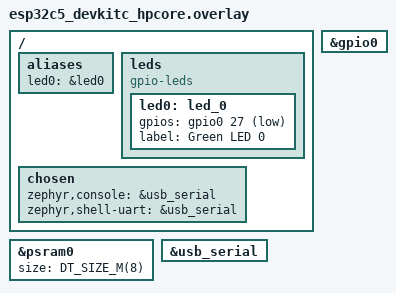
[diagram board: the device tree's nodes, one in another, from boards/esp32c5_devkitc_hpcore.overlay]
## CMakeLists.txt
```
# SPDX-License-Identifier: Apache-2.0

cmake_minimum_required(VERSION 3.20.0)

# Add wifi-credentials snippet
if(NOT wifi-credentials IN_LIST SNIPPET)
  set(SNIPPET wifi-credentials ${SNIPPET} CACHE STRING "wifi-credentials snippet" FORCE)
endif()

if(NOT espressif-psram-8M IN_LIST SNIPPET)
  set(SNIPPET espressif-psram-8M ${SNIPPET} CACHE STRING "espressif-psram-8M snippet" FORCE)
endif()

if(NOT espressif-psram-wifi IN_LIST SNIPPET)
  set(SNIPPET espressif-psram-wifi ${SNIPPET} CACHE STRING "espressif-psram-wifi snippet" FORCE)
endif()

set(mcuboot_key_file ${CMAKE_CURRENT_SOURCE_DIR}/key.pem)
set(mcuboot_CONFIG_BOOT_SIGNATURE_KEY_FILE "\"${mcuboot_key_file}\"")

# Load .env file into environment variables if it exists
if(EXISTS "${CMAKE_CURRENT_SOURCE_DIR}/.env")
  file(STRINGS "${CMAKE_CURRENT_SOURCE_DIR}/.env" ENV_VARS ENCODING UTF-8)
  foreach(line ${ENV_VARS})
    # Ignore empty lines and lines starting with '#'
    if(NOT line MATCHES "^[ \t]*#" AND line MATCHES "^([^=]+)=(.*)$")
      string(STRIP "${CMAKE_MATCH_1}" key)
      string(STRIP "${CMAKE_MATCH_2}" value)
      # Strip surrounding quotes if present
      string(REGEX REPLACE "^[\"\'](.*)[\"\']$" "\\1" value "${value}")
      set(ENV{${key}} "${value}")
    endif()
  endforeach()
endif()

find_package(Zephyr REQUIRED HINTS $ENV{ZEPHYR_BASE})
project(wifi)


# Verify that this sample is built through sysbuild to ensure MCUboot is
# automatically included and that sample specific MCUboot configurations are
# used when building MCUboot.
test_sysbuild()

FILE(GLOB app_sources src/*.c)
target_sources(app PRIVATE ${app_sources})

# From MQTT publisher sample
include(${ZEPHYR_BASE}/samples/net/common/common.cmake)
```

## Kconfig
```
# Config options for mqtt_publisher sample application

# Copyright (c) 2020 Intel Corporation
# SPDX-License-Identifier: Apache-2.0

mainmenu "Networking mqtt_publisher sample application"

config WIFI_SSID
	string "Wi-Fi SSID"
	default "$(WIFI_SSID)" if "$(WIFI_SSID)" != ""
	default "zephyr"

config WIFI_PASSWORD
	string "Wi-Fi Password"
	default "$(WIFI_PASSWORD)" if "$(WIFI_PASSWORD)" != ""
	default "19234567"

config WIFI_SECURITY_TYPE
	string "Wi-Fi Security Type"
	default "WIFI_SECURITY_TYPE_PSK"

config NET_SAMPLE_APP_MAX_ITERATIONS
	int "Number of times to Publish sample MQTT messages"
	default 500
	help
	  Send sample MQTT messages this many times in a MQTT connection
	  before exiting. A value of zero means that the messages are sent
	  forever.

config NET_SAMPLE_APP_MAX_CONNECTIONS
	int "Number of times to connect to the MQTT server"
	default 0
	help
	  Number of times to connect to the MQTT server. With each connection
	  send NET_SAMPLE_APP_MAX_ITERATIONS amount of MQTT sample messages.
	  A value of zero means to continue forever.

# From secure MQTT sample application
config NET_SAMPLE_MQTT_BROKER_HOSTNAME
	string "Hostname of MQTT broker"
	default "$(MQTT_BROKER)" if "$(MQTT_BROKER)" != ""
	default "test.mosquitto.org"
	help
	  MQTT broker's hostname or IP address.

config NET_SAMPLE_MQTT_BROKER_PORT
	string "MQTT Broker Connection Port"
	default "1883"
	help
	  Port through which the application should connect to the MQTT broker.
	  Secure MQTT uses port 8883.

config NET_SAMPLE_MQTT_PUB_TOPIC
	string "The MQTT topic the application should publish data to"
	default "technaid_sl/techstim"

config NET_SAMPLE_MQTT_SUB_TOPIC_CMD
	string "The MQTT topic the application will receive commands on"
	default "technaid_sl/techstim"

config NET_SAMPLE_MQTT_PUBLISH_INTERVAL
	int "Interval between MQTT publishes (in seconds)"
	default 10
	help
	  This config determines the frequency at which MQTT publishes occur.

choice NET_SAMPLE_MQTT_QOS
	prompt "Quality of Service level used for MQTT publish and subscribe"
	default NET_SAMPLE_MQTT_QOS_1_AT_LEAST_ONCE

config NET_SAMPLE_MQTT_QOS_0_AT_MOST_ONCE
	bool "QoS 0 / At most once delivery"
	help
	  No acknowledgment needed for published message.

config NET_SAMPLE_MQTT_QOS_1_AT_LEAST_ONCE
	bool "QoS 1 / At least once delivery"
	help
	  If acknowledgment expected for published message, duplicate messages permitted.

config NET_SAMPLE_MQTT_QOS_2_EXACTLY_ONCE
	bool "QoS 2 / Exactly once delivery"
	help
	   Acknowledgment expected and message shall be published only once.

endchoice

config NET_SAMPLE_MQTT_PAYLOAD_SIZE
	int "Size of MQTT payload in bytes"
	default 128

config TECHSTIM_DEV_DESC_PAYLOAD_SIZE
	int "Size of MQTT payload in bytes"
	default 512


source "Kconfig.zephyr"
```

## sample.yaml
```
common:
  harness: net
  tags:
    - net
    - wifi
sample:
  description: Test wifi driver and APIs functionality
  name: WiFi sample app
tests:
  sample.net.wifi:
    platform_allow:
      - cc3220sf_launchxl
      - disco_l475_iot1
      - reel_board
      - siwx917_rb4338a
    integration_platforms:
      - cc3220sf_launchxl
  sample.net.wifi.mikroe_wifi_bt_click:
    extra_args: SHIELD=mikroe_wifi_bt_click_mikrobus
    platform_allow: lpcxpresso55s69/lpc55s69/cpu0
  sample.net.wifi.esp_8266:
    extra_args: SHIELD=esp_8266
    platform_allow: sam4e_xpro
  sample.net.wifi.esp_8266_arduino:
    extra_args: SHIELD=esp_8266_arduino
    platform_allow:
      - frdm_k64f
      - disco_l475_iot1
    integration_platforms:
      - frdm_k64f
  sample.net.wifi.inventek_eswifi_arduino_uart:
    extra_args: SHIELD=inventek_eswifi_arduino_uart
    platform_allow:
      - frdm_k64f
      - nucleo_f767zi
    integration_platforms:
      - frdm_k64f
  sample.net.wifi.inventek_eswifi_arduino_spi:
    extra_args: SHIELD=inventek_eswifi_arduino_spi
    platform_allow:
      - frdm_k64f
      - nucleo_f767zi
    integration_platforms:
      - frdm_k64f
  sample.net.wifi.nrf70dk:
    extra_args:
      - CONFIG_BUILD_ONLY_NO_BLOBS=y
      - CONFIG_WIFI_CREDENTIALS=y
      - CONFIG_FLASH=y
      - CONFIG_FLASH_MAP=y
      - CONFIG_NVS=y
      - CONFIG_SETTINGS=y
    platform_allow:
      - nrf7002dk/nrf5340/cpuapp
      - nrf7002dk/nrf5340/cpuapp/nrf7001
    integration_platforms:
      - nrf7002dk/nrf5340/cpuapp
      - nrf7002dk/nrf5340/cpuapp/nrf7001
  sample.net.wifi.nrf7002ek:
    extra_args:
      - CONFIG_BUILD_ONLY_NO_BLOBS=y
      - SHIELD=nrf7002ek
    platform_allow:
      - nrf5340dk/nrf5340/cpuapp
      - nucleo_h723zg
    integration_platforms:
      - nrf5340dk/nrf5340/cpuapp
      - nucleo_h723zg
  sample.net.wifi.nrf7002eb:
    extra_args:
      - CONFIG_NRF70_UTIL=y
      - CONFIG_BUILD_ONLY_NO_BLOBS=y
      - SHIELD=nrf7002eb
    platform_allow:
      - thingy53/nrf5340/cpuapp
    integration_platforms:
      - thingy53/nrf5340/cpuapp
  sample.net.wifi.nrf7002eb2:
    extra_args:
      - CONFIG_BUILD_ONLY_NO_BLOBS=y
      - SHIELD=nrf7002eb2
    platform_allow:
      - nrf54lm20dk/nrf54lm20b/cpuapp
      - nrf54lm20dk/nrf54lm20b/cpuapp/ns
    integration_platforms:
      - nrf54lm20dk/nrf54lm20b/cpuapp
  sample.net.wifi.nxp_wifi:
    extra_args:
      - CONFIG_BUILD_ONLY_NO_BLOBS=y
    platform_allow:
      - frdm_rw612
      - rd_rw612_bga
  sample.net.wifi.esp32:
    extra_args:
      - CONFIG_BUILD_ONLY_NO_BLOBS=y
    platform_allow:
      - esp32_devkitc/esp32/procpu
      - esp32s2_devkitc
      - esp32c3_devkitc
      - esp32s3_devkitc/esp32s3/procpu
      - esp8684_devkitm
      - esp32c6_devkitc/esp32c6/hpcore
  sample.net.wifi.siwx91x_offloaded:
    extra_args:
      - CONFIG_WIFI_SILABS_SIWX91X_NET_STACK_OFFLOAD=y
    platform_allow:
      - siwx917_rb4338a
```

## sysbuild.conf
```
# Sysbuild configuration file.

# Enable MCUboot using overwrite only mode for this sample.
SB_CONFIG_BOOTLOADER_MCUBOOT=y
SB_CONFIG_MCUBOOT_MODE_OVERWRITE_ONLY=y
```

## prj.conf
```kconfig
CONFIG_EARLY_CONSOLE=y

CONFIG_NETWORKING=y
CONFIG_TEST_RANDOM_GENERATOR=y

CONFIG_MAIN_STACK_SIZE=5200
CONFIG_SHELL_STACK_SIZE=5200
CONFIG_NET_TX_STACK_SIZE=2048
CONFIG_NET_RX_STACK_SIZE=2048

CONFIG_NET_PKT_RX_COUNT=10
CONFIG_NET_PKT_TX_COUNT=10
CONFIG_NET_BUF_RX_COUNT=16
CONFIG_NET_BUF_TX_COUNT=16
CONFIG_NET_MAX_CONTEXTS=10
CONFIG_NET_DHCPV4=y

CONFIG_NET_IPV4=y
CONFIG_NET_IPV6=n

CONFIG_NET_TCP=y

CONFIG_NET_LOG=y
CONFIG_INIT_STACKS=y

CONFIG_NET_SHELL=y

CONFIG_NET_STATISTICS=y
CONFIG_NET_STATISTICS_PERIODIC_OUTPUT=n

CONFIG_WIFI=y
CONFIG_WIFI_LOG_LEVEL_ERR=y
CONFIG_NET_L2_WIFI_SHELL=y
# printing of scan results puts pressure on queues in new locking
# design in net_mgmt. So, use a higher timeout for a crowded
# environment.
CONFIG_NET_MGMT_EVENT_QUEUE_TIMEOUT=5000
CONFIG_NET_MGMT_EVENT_QUEUE_SIZE=16

# Implementing I2C shell
CONFIG_GPIO=y

CONFIG_I2C=y
CONFIG_I2C_SHELL=y

CONFIG_NET_BUF_POOL_USAGE=y
# CONFIG_ESP32_WIFI_STATIC_RX_MGMT_BUFFER=y
CONFIG_ESP32_WIFI_DYNAMIC_RX_MGMT_BUFFER=y

# From MQTT publisher sample
# Enable the MQTT Lib
CONFIG_MQTT_LIB=y
CONFIG_NET_LOG=y
CONFIG_NET_CONNECTION_MANAGER=y

CONFIG_POSIX_API=y

# CONFIG_NET_CONFIG_SETTINGS=y
# # CONFIG_NET_CONFIG_MY_IPV6_ADDR="2001:db8::1"
# # CONFIG_NET_CONFIG_PEER_IPV6_ADDR="2001:db8::2"

# # CONFIG_NET_CONFIG_MY_IPV4_ADDR="192.168.1.153"
# CONFIG_NET_CONFIG_PEER_IPV4_ADDR="192.168.1.146"

# Enable JSON
CONFIG_JSON_LIBRARY=y

# Change Serial prompt
CONFIG_SHELL_PROMPT_UART="techstim-uart:~$ "

CONFIG_REBOOT=y

# DFU config
CONFIG_IMG_MANAGER=y
CONFIG_MCUBOOT_IMG_MANAGER=y
CONFIG_MCUBOOT_SHELL=y
CONFIG_UPDATEABLE_IMAGE_NUMBER=1
CONFIG_MCUBOOT_BOOTUTIL_LIB=y

# # Flash
CONFIG_FLASH=y
CONFIG_STREAM_FLASH=y
CONFIG_FLASH_MAP=y
```

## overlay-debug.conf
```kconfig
# Debugging
CONFIG_STACK_SENTINEL=y
CONFIG_DEBUG_COREDUMP=y
CONFIG_DEBUG_COREDUMP_BACKEND_LOGGING=y
CONFIG_DEBUG_COREDUMP_MEMORY_DUMP_MIN=y
```

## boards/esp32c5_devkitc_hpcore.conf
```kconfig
# To solve issue relate to buffer after a Wi-Fi connection
CONFIG_ESP32_WIFI_DYNAMIC_RX_MGMT_BUFFER=y
```

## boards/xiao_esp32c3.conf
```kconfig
# Maximum power for WEMOS Lolin C3 is between [10, 12]
CONFIG_ESP32_PHY_MAX_TX_POWER=12
```

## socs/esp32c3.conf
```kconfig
CONFIG_ESP32_WIFI_STA_AUTO_DHCPV4=y
```

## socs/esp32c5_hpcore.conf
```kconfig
# CONFIG_ESP32_WIFI_STA_AUTO_DHCPV4=y
```

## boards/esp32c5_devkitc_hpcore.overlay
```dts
/ {
  aliases {
		led0 = &led0;
	};

	leds {
		compatible = "gpio-leds";

		led0: led_0 {
			gpios = <&gpio0 27 GPIO_ACTIVE_LOW>;
			label = "Green LED 0";
		};
	};

  chosen {
    zephyr,console = &usb_serial;
    zephyr,shell-uart = &usb_serial;
	};
};

&gpio0 {
    status = "okay";
};

&psram0 {
  size = <DT_SIZE_M(8)>;
};

&usb_serial {
  status = "okay";
};
```

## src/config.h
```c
/*
 * Copyright (c) 2017 Intel Corporation
 *
 * SPDX-License-Identifier: Apache-2.0
 */

/**
 * TODO:
 * - [] Update IP when there is a Wi-Fi Connection
 * - [] Add the MAC address
 */

#ifndef __CONFIG_H__
#define __CONFIG_H__

#define NO_SERVER_ADDR "0.0.0.0"
#define DEFAULT_SERVER_ADDR CONFIG_NET_SAMPLE_MQTT_BROKER_HOSTNAME

#ifdef CONFIG_NET_CONFIG_SETTINGS
#ifdef CONFIG_NET_IPV6
#define ZEPHYR_ADDR CONFIG_NET_CONFIG_MY_IPV6_ADDR
#define SERVER_ADDR CONFIG_NET_CONFIG_PEER_IPV6_ADDR
#else
#define ZEPHYR_ADDR CONFIG_NET_CONFIG_MY_IPV4_ADDR
#define SERVER_ADDR CONFIG_NET_CONFIG_PEER_IPV4_ADDR
#endif
#else
#ifdef CONFIG_NET_IPV6
#define ZEPHYR_ADDR "2001:db8::1"
#define SERVER_ADDR "2001:db8::2"
#else
#define ZEPHYR_ADDR "192.168.1.101"
#define SERVER_ADDR "0.0.0.0"
#endif
#endif

#if defined(CONFIG_SOCKS)
#define SOCKS5_PROXY_ADDR SERVER_ADDR
#define SOCKS5_PROXY_PORT 1080
#endif

#ifdef CONFIG_MQTT_LIB_TLS
#ifdef CONFIG_MQTT_LIB_WEBSOCKET
#define SERVER_PORT 9001
#else
#define SERVER_PORT 8883
#endif /* CONFIG_MQTT_LIB_WEBSOCKET */
#else
#ifdef CONFIG_MQTT_LIB_WEBSOCKET
#define SERVER_PORT 9001
#else
#define SERVER_PORT 1883
#endif /* CONFIG_MQTT_LIB_WEBSOCKET */
#endif

#define APP_CONNECT_TIMEOUT_MS 2000
#define APP_SLEEP_MSECS 500

#define APP_CONNECT_TRIES 10

#define APP_MQTT_BUFFER_SIZE 128

#define APP_MQTT_KEEPALIVE 4

// MQTT definitions
#define PRODUCT_ID "S0"     // User defined: Where Sx; x= 1,2,4, etc. is for PU, while Sy; y=A, B, C, etc. for CU
#define SERIAL_NUMBER "pu1" // It will be extracted from EFUSE_BLK3 (USER_DATA)

#define MQTT_COMPANY "technaid_sl"
#define MQTT_PRODUCT "techstim"
#define MQTT_PUBLISH_DEVICE_DESCRIPTOR MQTT_COMPANY "/" MQTT_PRODUCT "/" SERIAL_NUMBER "/device_descriptor"
#define MQTT_PUBLISH_PARAMETERS MQTT_COMPANY "/" MQTT_PRODUCT "/" SERIAL_NUMBER "/parameters"
#define MQTT_PUBLISH_INFO MQTT_COMPANY "/" MQTT_PRODUCT "/" SERIAL_NUMBER "/info"
#define MQTT_SUBSCRIBE_IDS MQTT_COMPANY "/" MQTT_PRODUCT "/" SERIAL_NUMBER "/ids"

// #define TARGETS_ARRAY "[" SERIAL_NUMBER "," SERIAL_NUMBER "]"
#define TARGETS_ARRAY "[" SERIAL_NUMBER "," SERIAL_NUMBER "]"

/* descriptor en un único literal de bytes (Little‑Endian) */
#define DEVICE_DESCRIPTOR_BYTES                               \
    "\x26"                     /* Length = 38 */              \
    "\x00\x04"                 /* DescriptorVersion = 1024 */ \
    "\x00"                     /* DeviceClass */              \
    "\x01"                     /* DeviceSubClass */           \
    "\x01"                     /* DeviceID */                 \
    "\x02"                     /* DeviceProtocol */           \
    "\x0D"                     /* MaxPacketSize */            \
    "\x39\x30"                 /* Vendor = 12345 */           \
    "\x0D"                     /* Product */                  \
    "\x00\x04"                 /* BCDDevice = 1024 */         \
    "\x7B\x00\x00\x00"         /* SerialNumber = 123 */       \
    "\x10"                     /* IDs */                      \
    "\x00\x10"                 /* HardwareVersion = 4096 */   \
    "\x00\x04"                 /* FirmwareVersion = 1024 */   \
    "\x0D"                     /* ProtocolsSupported */       \
    "\x68\x01\xA8\xC0"         /* WIP = 192.168.1.104 */      \
    "\x00\x00\x00\x00"         /* CANID */                    \
    "\xB7\x3A\x11\x44\x1B\x00" /* MAC = 00:1B:44:11:3A:B7 */  \
    "\xB8\x0B"                 /* Port = 3000 */              \
    "\x00\xC2\x01\x00"         /* ByteSpeed = 115200 */

/* longitud en bytes */
#define DEVICE_DESCRIPTOR_LEN sizeof(DEVICE_DESCRIPTOR_BYTES) - 1

#define DEVICE_DESCRIPTOR_MACRO "{\n \
\"Length\": 38,\n \
\"DescriptorVersion\": 1024,\n \
\"DeviceClass\": 0,\n \
\"DeviceSubClass\": 1,\n \
\"DeviceID\": 1,\n \
\"DeviceProtocol\": 2,\n \
\"MaxPacketSize\": 13,\n \
\"Vendor\": 12345,\n \
\"Product\": 13,\n \
\"BCDDevice\": 1024,\n \
\"SerialNumber\": 123,\n \
\"IDs\": 16,\n \
\"HardwareVersion\": 4096,\n \
\"FirmwareVersion\": 1024,\n \
\"ProtocolsSupported\": 13,\n \
\"WIP\": 3232235880,\n \
\"CANID\": 0,\n \
\"MAC\": 117106096823,\n \
\"Port\": 3000,\n \
\"ByteSpeed\": 115200,\n \
}"

/* descriptor genérico de un dispositivo Techstim */
typedef struct
{
    uint8_t Length;             /* 38 bytes totales */
    uint16_t DescriptorVersion; /* 1024  (v0.4.0) */
    uint8_t DeviceClass;        /* 0 → Techstim */
    uint8_t DeviceSubClass;     /* 1 → Techstim v2 */
    uint16_t DeviceID;          /* 1 → SA */
    uint8_t DeviceProtocol;     /* 2 → Wi‑Fi */
    uint8_t MaxPacketSize;      /* 13 */
    uint16_t Vendor;            /* 12345  Technaid SL */
    uint8_t Product;            /* 13  Techstim Wi‑Fi register ID */
    uint16_t BCDDevice;         /* 1024  release */
    uint32_t SerialNumber;      /* 123 */
    uint8_t IDs;                /* 16 */
    uint16_t HardwareVersion;   /* 4096  (v0.4.0) */
    uint16_t FirmwareVersion;   /* 1024  (v1.0.0) */
    uint8_t ProtocolsSupported; /* 13 → USB,BT,Wi‑Fi */
    uint32_t WIP;               /* IP en formato host (0xC0A80168=192.168.1.104) */
    uint32_t CANID;             /* 0 → ninguno */
    uint64_t MAC;               /* 0x001B44113AB7 = 00:1B:44:11:3A:B7 */
    uint16_t Port;              /* 3000 */
    uint32_t ByteSpeed;         /* 115200 */
} device_descriptor_t;


/* Estructuras para parámetros de configuración */
typedef struct
{
    int16_t pos_amp[4];
    size_t pos_amp_len;
} pos_amp_t;

typedef struct
{
    int16_t neg_amp[4];
    size_t neg_amp_len;
} neg_amp_t;

typedef struct
{
    int16_t pos_time[4];
    size_t pos_time_len;
} pos_time_t;

typedef struct
{
    int16_t neg_time[4];
    size_t neg_time_len;
} neg_time_t;

typedef struct
{
    int16_t motor_amp[4];
    size_t motor_amp_len;
} umbral_motor_t;

typedef struct
{
    int16_t comfort_amp[4];
    size_t comfort_amp_len;
} umbral_comfort_t;

typedef struct
{
    int16_t max_amp[4];
    size_t max_amp_len;
} max_current_t;

typedef struct
{
    int16_t min_amp[4];
    size_t min_amp_len;
} min_current_t;

/**
 * Parameter index map for product configuration.
 * These values were previously defined as individual PARAM_* macros.
 */
typedef struct
{
    pos_amp_t pos_amp; // Positive amplitude for channels 1-4 [0-100 mA]
    neg_amp_t neg_amp; // Negative amplitude for channels 1-4 [0-100 mA]
    pos_time_t pos_time; // Positive pulse time for channels 1-4 [0-1000 µs]
    neg_time_t neg_time; // Negative pulse time for channels 1-4 [0-1000 µs]

    uint8_t order_channels; // Order of channels [0-3]
    uint8_t repetitions;    // Number of repetitions [single: 0, double: 1, triple: 2]
    uint8_t inv_pulse;      // Invert pulse [0-1]

    umbral_motor_t umbral_motor;   // Motor threshold for channels 1-4 [0-100 mA]
    umbral_comfort_t umbral_comfort; // Comfort threshold for channels 1-4 [0-100 mA]

    min_current_t min_current; // Minimum current for channels 1-4 [0-100 mA]
    max_current_t max_current; // Maximum current for channels 1-4 [0-100 mA]

    uint16_t intra_freq; // Intra-group frequency [0-200 Hz]
    uint16_t group_freq; // Group frequency [0-200 Hz]

    uint16_t upgrade_ramp;   // Upgrade ramp time [0-1000 ms]
    uint16_t downgrade_ramp; // Downgrade ramp time [0-1000 ms]

    uint16_t stimulation_mode; // Stimulation mode [Symmetric: 0, Asymmetric: 1]
    uint16_t delay;            // Delay between positive and negative pulse [100-1000 ms]

    uint16_t device_id;        // Device ID [PRODUCT_ID]
    uint16_t firmware_version; // Firmware version [4096 for v1.0.0, SOFTWARE_VERSION_SEMVER]
    uint16_t error;            // Error code [0 for no error, otherwise specific error codes]
    uint16_t status;           // Status code bitmask ([0/1]: stimulation inactive/active; bit 0: channel 1, bit 1: channel 2, etc.)
    uint16_t enabled;          // Enabled channels bitmask (bit 0 for channel 1, bit 1 for channel 2, etc.)

    uint16_t log_counter; // Log counter for tracking parameter changes (incremented on each change)
    uint16_t qualifier;   // Qualifier Card ID index for the product (similar to PRODUCT_ID)
} parameters_t;

/*******************************************************************************
 *  FIRMWARE VERSION AND CARD ID                                               *
 ******************************************************************************/
#ifdef APPVERSION
#define SOFTWARE_VERSION APP_VERSION_STRING // String format for SW version
// #define SOFTWARE_VERSION_SEMVER ((APP_VERSION_NUMBER) >> 4U)                                                      /* MAJOR.MINOR.PATCH [0xM.mm.P] */
#define SOFTWARE_VERSION_SEMVER ((APP_VERSION_MAJOR << 12U) + (APP_VERSION_MINOR << 4U) + (APP_PATCHLEVEL << 0U)) /* MAJOR.MINOR.PATCH [0xM.mm.P] */
#else
#define SOFTWARE_VERSION "v1.0.0"      // String format for SW version
#define SOFTWARE_VERSION_SEMVER 0x1000U /* MAJOR.MINOR.PATCH [0xM.mm.P] */
#endif

#define HARDWARE_VERSION_SEMVER 0x1000U   /* MAJOR.MINOR.PATCH [0xM.mm.P] */
#define RELEASE_VERSION_SEMVER 0x1000U    /* MAJOR.MINOR.PATCH [0xM.mm.P] */
#define DESCRIPTOR_VERSION_SEMVER 0x1000U /* MAJOR.MINOR.PATCH [0xM.mm.P] */

#define KIND_ID 83    // 'S' in ASCII DEC (0x53) for Tech'S'tim := Stimulation
#define DEFAULT_ID 48 // '0' in ASCII DEC (0x30) for first device
// #define PRODUCT_ID (((KIND_ID) << 8) | (DEFAULT_ID))

#define MAX_PARAMS 68 // [A-Z][AA-AZ][BA-BP]

// Info status values
#define INFO_STATUS_CONNECTED "connected"
#define INFO_STATUS_DISCONNECTED "disconnected"

// Info mode values
#define INFO_MODE_CONTROLLER "controller"   // Controller for PU units
#define INFO_MODE_PERIPHERAL "peripheral"   // Peripheral for CU units

#define MQTT_CLIENTID PRODUCT_ID

#endif
```

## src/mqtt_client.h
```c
/*
 * Copyright (c) 2024 Analog Devices, Inc.
 *
 * SPDX-License-Identifier: Apache-2.0
 */

#ifndef __MQTT_CLIENT_H__
#define __MQTT_CLIENT_H__

/** MQTT connection timeouts */
#define MSECS_NET_POLL_TIMEOUT 5000
#define MSECS_WAIT_RECONNECT 1000

/** MQTT connection status flag */
extern bool mqtt_connected;

/**
 *  @brief Initialise the MQTT client & broker configuration
 */
int app_mqtt_init(struct mqtt_client *client, char *addr);

/**
 *  @brief Blocking function that establishes connectivity to the MQTT broker
 */
void app_mqtt_connect(struct mqtt_client *client);

/**
 *  @brief  Subscribes to user-defined MQTT topics and continuously
 *          processes incoming data while the MQTT connection is active
 */
void app_mqtt_run(struct mqtt_client *client);

/**
 *  @brief   Subscribe to user-defined MQTT topics
 */
int app_mqtt_subscribe(struct mqtt_client *client);

/**
 *  @brief  Publish MQTT payload
 */
int app_mqtt_publish(struct mqtt_client *client);

/**
 * @brief  Publish MQTT payload with status topic
 */
int app_mqtt_publish_status(struct mqtt_client *client);

/**
 * @brief  Publish MQTT payload with mode topic
 */
int app_mqtt_publish_mode(struct mqtt_client *client);

/**
 * @brief  Publish MQTT payload with targets topic
 */
int app_mqtt_publish_targets(struct mqtt_client *client);

/**
 * @brief  Publish MQTT payload with device descriptor topic
 */
int app_mqtt_publish_descriptor(struct mqtt_client *client);

/**
 * @brief  Publish MQTT payload with parameters topic
 */
int app_mqtt_publish_parameters(struct mqtt_client *client);

/**
 * @brief  Process incoming MQTT data and handle keepalive
 */
int app_mqtt_process(struct mqtt_client *client);

#endif /* __MQTT_CLIENT_H__ */
```

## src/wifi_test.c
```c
/*
 * Copyright (c) 2016 Intel Corporation.
 *
 * SPDX-License-Identifier: Apache-2.0
 */

/**
 * TODO:
 * - [] Add blinking error when device is not connect to the Wi-Fi.
 * - [] Add IDs commands
 * FIXME:
 * - [] main thread is overflow memory. Check what is happening.
 */

#include <zephyr/kernel.h>
#include <errno.h>

#include <stdio.h>
#include <zephyr/drivers/gpio.h>

// From MQTT publisher sample
#include <zephyr/logging/log.h>
LOG_MODULE_REGISTER(net_mqtt_publisher_sample, LOG_LEVEL_DBG);

#include <zephyr/posix/poll.h>
#include <zephyr/posix/arpa/inet.h>

#include <zephyr/net/socket.h>
#include <zephyr/net/mqtt.h>
#include <zephyr/random/random.h>
#if defined(CONFIG_LOG_BACKEND_MQTT)
#include <zephyr/logging/log_backend_mqtt.h>
#endif

#include <string.h>

#include "config.h"
#include "net_sample_common.h"

// Obtain IP
#include <zephyr/net/net_if.h>
#include <zephyr/net/net_ip.h>
#include <zephyr/net/wifi_mgmt.h>
#include <zephyr/net/wifi_credentials.h>

#include "mqtt_client.h"

// Version control
#include <zephyr/app_version.h>

// Register new shell commands
#include <zephyr/shell/shell.h>

// Adding default wifi credentials for autoconnect
#include <zephyr/net/wifi_credentials.h>

const char *ssid = CONFIG_WIFI_SSID;
const char *password = CONFIG_WIFI_PASSWORD;
enum wifi_security_type type = WIFI_SECURITY_TYPE_PSK;


#ifdef CONFIG_BOARD_XIAO_ESP32C5
/* 1000 msec = 1 sec */
#define SLEEP_TIME_MS 1000
/* The devicetree node identifier for the "led0" alias. */
#define LED0_NODE DT_ALIAS(led0)

extern uint8_t payload_parameters_buf[CONFIG_TECHSTIM_DEV_DESC_PAYLOAD_SIZE];

extern bool mqtt_connected;

/*
 * A build error on this line means your board is unsupported.
 * See the sample documentation for information on how to fix this.
 */
static const struct gpio_dt_spec led = GPIO_DT_SPEC_GET(LED0_NODE, gpios);

#endif

/* MQTT publish work item */
struct k_work_delayable mqtt_publish_work;

static char server_addr[INET_ADDRSTRLEN] = SERVER_ADDR;

/* Buffers for MQTT client. */
static uint8_t rx_buffer[APP_MQTT_BUFFER_SIZE];
static uint8_t tx_buffer[APP_MQTT_BUFFER_SIZE];

/* The mqtt client struct */
static struct mqtt_client client_ctx;

/* MQTT Broker details. */
static struct sockaddr_storage broker;

static struct pollfd fds[1];
static int nfds;
static bool connected;

/* Whether to include full topic in the publish message, or alias only (MQTT 5). */
static bool include_topic;
static bool aliases_enabled;

// Shell command function
static int cmd_version(const struct shell *sh, size_t argc, char **argv)
{
	ARG_UNUSED(argc);
	ARG_UNUSED(argv);

	shell_print(sh, "Showing parameters values:");
	shell_print(sh, "parameters: %s", payload_parameters_buf);
	shell_print(sh, "TechStim App version %d.%d.%d", APP_VERSION_MAJOR, APP_VERSION_MINOR, APP_PATCHLEVEL);

	return 0;
}

SHELL_CMD_ARG_REGISTER(s, NULL, "Show parameters", cmd_version, 1, 0);

#define WIFI_MGMT_EVENTS (NET_EVENT_WIFI_CONNECT_RESULT | NET_EVENT_WIFI_DISCONNECT_RESULT)

static struct net_mgmt_event_callback wifi_mgmt_cb;

static void wifi_mgmt_event_handler(struct net_mgmt_event_callback *cb,
				    uint64_t mgmt_event, struct net_if *iface)
{
	const struct wifi_status *status = (const struct wifi_status *)cb->info;

	ARG_UNUSED(iface);

	switch (mgmt_event) {
	case NET_EVENT_WIFI_CONNECT_RESULT:
		if (status->status) {
			LOG_ERR("Wi-Fi connection failed (%d), reason: %u, status: %u",
				status->status, status->reason_code, status->status_code);
		} else {
			LOG_INF("Wi-Fi connected successfully");
		}
		break;
	case NET_EVENT_WIFI_DISCONNECT_RESULT:
		LOG_INF("Wi-Fi disconnected (status: %d)", status->status);
		break;
	default:
		break;
	}
}

static int wifi_autoconnect_from_nvs(void)
{
	struct net_if *iface = net_if_get_wifi_sta();
	int ret;

	if (iface == NULL)
	{
		iface = net_if_get_default();
	}

	if (iface == NULL)
	{
		LOG_ERR("No default or Wi-Fi STA network interface");
		return -ENODEV;
	}

	if (wifi_credentials_is_empty())
	{
		LOG_WRN("No Wi-Fi credentials save in NVS");
		return -ENOENT;
	}

#ifdef CONFIG_WIFI_CREDENTIALS_CONNECT_STORED
	ret = net_mgmt(NET_REQUEST_WIFI_CONNECT_STORED, iface, NULL, 0);
	if (ret)
	{
		LOG_ERR("Auto-connect request failed: %d", ret);
		return ret;
	}

	LOG_INF("Auto-connect requested using saved Wi-Fi credentials");
	return 0;
#else
	LOG_ERR("CONFIG_WIFI_CREDENTIALS_CONNECT_STORED is not enabled");
	return -ENOTSUP;
#endif
}

static void prepare_fds(struct mqtt_client *client)
{
	if (client->transport.type == MQTT_TRANSPORT_NON_SECURE)
	{
		fds[0].fd = client->transport.tcp.sock;
	}
#if defined(CONFIG_MQTT_LIB_TLS)
	else if (client->transport.type == MQTT_TRANSPORT_SECURE)
	{
		fds[0].fd = client->transport.tls.sock;
	}
#endif

	fds[0].events = POLLIN;
	nfds = 1;
}

/** The system work queue is used to handle periodic MQTT publishing.
 *  Work queuing begins when the MQTT connection is established.
 *  Use CONFIG_NET_SAMPLE_MQTT_PUBLISH_INTERVAL to set the publish frequency.
 */

static void publish_work_handler(struct k_work *work)
{
	int rc;
	static bool first_msg = true;

	if (mqtt_connected)
	{
		if (first_msg)
		{
			LOG_INF("Publishing first MQTT message...");
			first_msg = false;
			// rc = app_mqtt_publish(&client_ctx);
			rc = app_mqtt_publish_status(&client_ctx);
			rc += app_mqtt_publish_mode(&client_ctx);
			rc += app_mqtt_publish_targets(&client_ctx);
			rc += app_mqtt_publish_descriptor(&client_ctx);
		}
		else
		{
			rc = app_mqtt_publish_parameters(&client_ctx);
		}
		if (rc != 0)
		{
			LOG_INF("MQTT Publish failed [%d]", rc);
		}
		k_work_reschedule(&mqtt_publish_work,
						  K_SECONDS(CONFIG_NET_SAMPLE_MQTT_PUBLISH_INTERVAL));
	}
	else
	{
		k_work_cancel_delayable(&mqtt_publish_work);
	}
}

int main(void)
{
	int ret;

	LOG_INF("TechStim App version: %d.%d.%d", APP_VERSION_MAJOR, APP_VERSION_MINOR, APP_PATCHLEVEL);

#ifdef CONFIG_BOARD_XIAO_ESP32C5
	LOG_INF("Starting Wi-Fi test with LED indication");
	bool led_state = false;

	if (!gpio_is_ready_dt(&led))
	{
		return 0;
	}

	ret = gpio_pin_configure_dt(&led, GPIO_OUTPUT_ACTIVE);
	if (ret < 0)
	{
		return 0;
	}

	ret = gpio_pin_set_dt(&led, led_state);
	if (ret < 0)
	{
		return 0;
	}

	LOG_INF("LED state: %s", led_state ? "ON" : "OFF");
#else
	LOG_INF("Starting Wi-Fi test without LED indication");
#endif

	/* Register Wi-Fi management event callback to monitor connection results */
	net_mgmt_init_event_callback(&wifi_mgmt_cb, wifi_mgmt_event_handler, WIFI_MGMT_EVENTS);
	net_mgmt_add_event_callback(&wifi_mgmt_cb);

	// Test Wifi autoconnect using credentials function to load credentials from Kconfig file
	// and connect to Wi-Fi network. This is optional, as credentials can also be loaded from NVS.
	ret = wifi_credentials_set_personal(
		ssid, strlen(ssid),
		type,
		NULL, 0, // BSSID (NULL if not fixed)
		password, strlen(password),
		0,       // flags
		0,       // channel (0 for any)
		0        // timeout (0 for default)
	);

	if (ret == 0) {
		// Success
		LOG_INF("Wi-Fi credentials set successfully for Kconfig: %s", ssid);
	}
	else {
		// Failure
		LOG_ERR("Failed to set Wi-Fi credentials for Kconfig: %s, error code: %d", ssid, ret);
	}

	ret = wifi_autoconnect_from_nvs();
	if (ret < 0)
	{
		LOG_WRN("Wi-Fi autoconnect skipped (%d)", ret);
	}

	wait_for_network();

	struct net_if *iface = net_if_get_wifi_sta();
	if (!iface)
	{
		LOG_INF("No default network interface");
	}
	else
	{
		struct net_if_ipv4 *ipv4 = iface->config.ip.ipv4;
		char buf[NET_IPV6_ADDR_LEN];

		struct in_addr *addr = &ipv4->unicast[0].ipv4.address.net_in_addr;
		// Conversión segura a string
		// sys_le32_to_cpu((net_in_addr)addr.s_addr); // Opcional si ya es host-endian
		net_addr_ntop(AF_INET, &(addr->s_addr), buf, sizeof(buf));

		// Impresión del resultado
		LOG_INF("Dirección IP: %s", buf);

		if (strcmp(server_addr, NO_SERVER_ADDR) == 0)
		{
			LOG_WRN("SERVER_ADDR is empty, assigning new value");
			char new_server_addr[INET_ADDRSTRLEN] = DEFAULT_SERVER_ADDR;
			strncpy(server_addr, new_server_addr, sizeof(new_server_addr));
			LOG_INF("Broker address: %s", server_addr);
		}
		else
		{
			LOG_INF("Broker address: %s", server_addr);
		}

		int rc = app_mqtt_init(&client_ctx, server_addr);
		if (rc != 0)
		{
			LOG_ERR("MQTT Init failed [%d]", rc);
			return rc;
		}

		/* Initialise MQTT publish work item */
		k_work_init_delayable(&mqtt_publish_work, publish_work_handler);
		
		/* Thread main loop */
		while (1)
		{

#ifdef CONFIG_BOARD_XIAO_ESP32C5
			ret = gpio_pin_toggle_dt(&led);
			if (ret < 0)
			{
				return 0;
			}

			led_state = !led_state;
			LOG_INF("LED state: %s", led_state ? "ON" : "OFF");
#endif

			/* Block until MQTT connection is up */
			app_mqtt_connect(&client_ctx);

			/* We are now connected, begin queueing periodic MQTT publishes */
			k_work_reschedule(&mqtt_publish_work,
							  K_SECONDS(CONFIG_NET_SAMPLE_MQTT_PUBLISH_INTERVAL));

			/* Handle MQTT inputs and connection */
			app_mqtt_run(&client_ctx);
			k_msleep(SLEEP_TIME_MS);
		}
	}

	LOG_INF("Connected to Wi-Fi");

	// exit(start_app());

	return 0;
}
```
